AUTOSAR XML (schema 4-2-1)
package /ComponentTypes
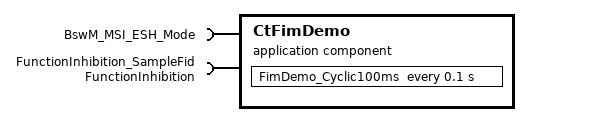
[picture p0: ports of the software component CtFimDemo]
  application sw component type CtFimDemo  # Short demonstration component for FiM handling. Currently, this is cyclic polling of a sample FID.
    require port BswM_MSI_ESH_Mode: mode-switch-receiver-com-spec{enhanced-mode-api=false, supports-asynchronous-mode-switch=false}, required-interface=BswM_MSI_ESH_Mode
    require port FunctionInhibition_SampleFid: client-com-spec=GetFunctionPermission, required-interface=FunctionInhibition
    behavior CtFimDemo_InternalBehavior: data-type-mapping=DemoTypeMapping
      timing event TMT_FimDemo_Cyclic100ms: start-on-event=FimDemo_Cyclic100ms, period=0.1
        disabled-mode:
          BswM_MSI_ESH_Mode.BswM_MDGP_ESH_Mode.SHUTDOWN
          BswM_MSI_ESH_Mode.BswM_MDGP_ESH_Mode.STARTUP
          BswM_MSI_ESH_Mode.BswM_MDGP_ESH_Mode.WAKEUP
      runnable FimDemo_Cyclic100ms
        sync call SC_FunctionInhibition_SampleFid_GetFunctionPermission: operation=FunctionInhibition_SampleFid.GetFunctionPermission, timeout=0
  swc implementation CtFimDemo_Implementation: behavior=CtFimDemo_InternalBehavior
    code-descriptors:
      code Default: artifact-descriptors=autosar-engineering-object={short-label=Default, category=SWSRC}
